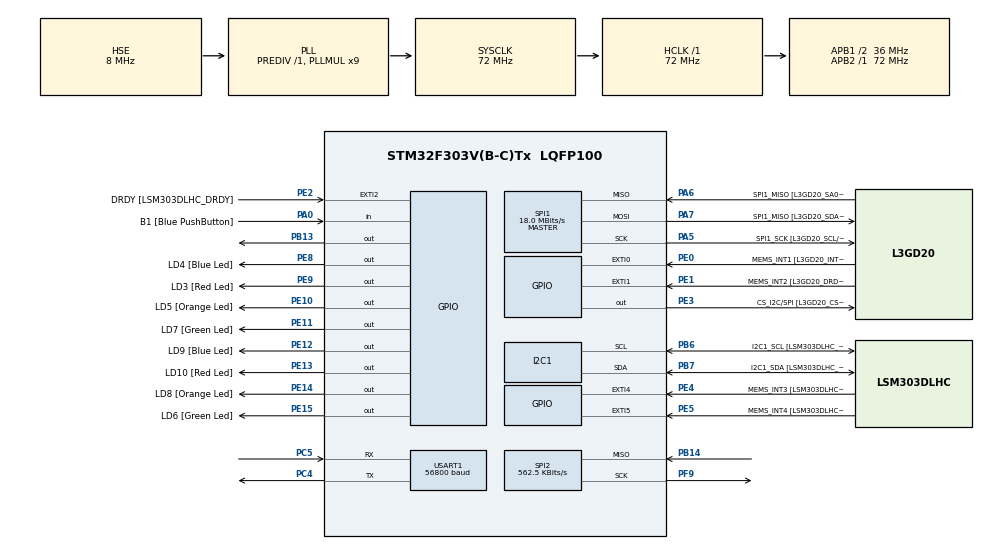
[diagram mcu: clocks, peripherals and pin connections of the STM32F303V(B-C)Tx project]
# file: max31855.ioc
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Mcu.Family=STM32F3
PA6.Mode=Full_Duplex_Master
RCC.CortexFreq_Value=72000000
SPI1.VirtualType=VM_MASTER
SPI2.VirtualType=VM_MASTER
PE11.GPIO_Label=LD7 [Green Led]
USART1.BaudRate=56800
PA14.GPIO_Label=SWCLK
RCC.SYSCLKSourceVirtual=RCC_SYSCLKSOURCE_PLLCLK
PA0.GPIO_Label=B1 [Blue PushButton]
PA6.GPIO_Label=SPI1_MISO [L3GD20_SA0/SDO]
PB6.GPIO_Label=I2C1_SCL [LSM303DLHC_SCL]
PC5.Mode=Asynchronous
PB13.Signal=GPIO_Output
PC15-OSC32_OUT.GPIO_Label=OSC32_OUT
ProjectManager.StackSize=0x400
VP_FREERTOS_VS_CMSIS_V2.Mode=CMSIS_V2
SPI1.Mode-Full_Duplex_Master=SPI_MODE_MASTER
PA12.Signal=USB_DP
SPI2.CLKPolarity=SPI_POLARITY_HIGH
SPI1.Direction=SPI_DIRECTION_2LINES
RCC.HCLKFreq_Value=72000000
RCC.APB2TimFreq_Value=72000000
PB6.Signal=I2C1_SCL
PB13.GPIO_ModeDefaultOutputPP=GPIO_MODE_OUTPUT_PP
PB6.Mode=I2C
SPI1.CalculateBaudRate=18.0 MBits/s
PE5.Signal=GPXTI5
PE1.Signal=GPXTI1
RCC.AHBFreq_Value=72000000
SPI2.BaudRatePrescaler=SPI_BAUDRATEPRESCALER_64
RCC.HSE_VALUE=8000000
PF0-OSC_IN.GPIO_Label=OSC_IN
RCC.PLLMUL=RCC_PLL_MUL9
NVIC.TIM1_TRG_COM_TIM17_IRQn=true\:0\:0\:false\:false\:true\:false\:false\:true
PF9.Mode=RX_Only_Simplex_Unidirect_Master
PE13.Signal=GPIO_Output
PE9.Signal=GPIO_Output
PA14.Mode=Serial_Wire
PB14.Mode=RX_Only_Simplex_Unidirect_Master
PE4.GPIO_Label=MEMS_INT3 [LSM303DLHC_INT1]
SPI2.CalculateBaudRate=562.5 KBits/s
PE2.Signal=GPXTI2
PB7.Signal=I2C1_SDA
PE10.Signal=GPIO_Output
PE4.Signal=GPXTI4
SPI1.CalculateBaudRate-Full_Duplex_Master=24.0 MBits/s
PA0.Signal=GPIO_Input
PB7.GPIO_Label=I2C1_SDA [LSM303DLHC_SDA]
Mcu.Package=LQFP100
PA6.Signal=SPI1_MISO
NVIC.TimeBase=TIM1_TRG_COM_TIM17_IRQn
SPI2.Mode=SPI_MODE_MASTER
NVIC.TimeBaseIP=TIM17
PE12.GPIO_Label=LD9 [Blue Led]
SPI2.CLKPhase=SPI_PHASE_2EDGE
PE0.GPIO_Label=MEMS_INT1 [L3GD20_INT1]
RCC.APB1TimFreq_Value=72000000
PC14-OSC32_IN.GPIO_Label=OSC32_IN
SPI2.Direction=SPI_DIRECTION_2LINES_RXONLY
PC5.Signal=USART1_RX
PE10.GPIO_Label=LD5 [Orange Led]
SPI1.BaudRatePrescaler=SPI_BAUDRATEPRESCALER_4
PE2.GPIO_Label=DRDY [LSM303DLHC_DRDY]
PF1-OSC_OUT.Signal=RCC_OSC_OUT
PC4.Mode=Asynchronous
PA5.Mode=Full_Duplex_Master
PB3.GPIO_Label=SWO
RCC.PLLSourceVirtual=RCC_PLLSOURCE_HSE
FREERTOS.Tasks01=defaultTask,24,128,StartDefaultTask,Default,NULL,Dynamic,NULL,NULL
PA7.Mode=Full_Duplex_Master
VP_SYS_VS_tim17.Mode=TIM17
PC4.Signal=USART1_TX
PE4.GPIO_ModeDefaultEXTI=GPIO_MODE_EVT_RISING
PA11.GPIO_Label=DM
PE14.GPIO_Label=LD8 [Orange Led]
PE1.GPIO_ModeDefaultEXTI=GPIO_MODE_EVT_RISING
RCC.APB1CLKDivider=RCC_HCLK_DIV2
PC14-OSC32_IN.Signal=RCC_OSC32_IN
PA12.GPIO_Label=DP
USART1.VirtualMode-Asynchronous=VM_ASYNC
PA13.Signal=SYS_JTMS-SWDIO
PE15.GPIO_Label=LD6 [Green Led]
ProjectManager.TargetToolchain=EWARM V8
PE5.GPIO_ModeDefaultEXTI=GPIO_MODE_EVT_RISING
PE8.GPIO_Label=LD4 [Blue Led]
PE0.GPIO_ModeDefaultEXTI=GPIO_MODE_EVT_RISING
PB13.GPIO_Speed=GPIO_SPEED_FREQ_HIGH
RCC.USBFreq_Value=48000000
PE11.Signal=GPIO_Output
RCC.LSE_VALUE=32768
PC15-OSC32_OUT.Signal=RCC_OSC32_OUT
PE9.GPIO_Label=LD3 [Red Led]
PF0-OSC_IN.Mode=HSE-External-Clock-Source
PB14.Signal=SPI2_MISO
PA5.Signal=SPI1_SCK
board=STM32F3DISCOVERY
PE1.GPIO_Label=MEMS_INT2 [L3GD20_DRDY/INT2]
PB13.GPIO_PuPd=GPIO_PULLUP
RCC.APB2Freq_Value=72000000
PE14.Signal=GPIO_Output
PE15.Signal=GPIO_Output
RCC.PRESCALERUSB=RCC_USBCLKSOURCE_PLL_DIV1_5
PE8.Signal=GPIO_Output
SPI1.Mode=SPI_MODE_MASTER
PF1-OSC_OUT.GPIO_Label=OSC_OUT
I2C1.Timing-I2C=0x2000090E
PA13.Mode=Serial_Wire
Mcu.Name=STM32F303V(B-C)Tx
PE0.Signal=GPXTI0
PE12.Signal=GPIO_Output
PA13.GPIO_Label=SWDIO
PB3.Signal=SYS_JTDO-TRACESWO
RCC.SYSCLKFreq_VALUE=72000000
PA7.GPIO_Label=SPI1_MISO [L3GD20_SDA/SDI/SDO]
PE13.GPIO_Label=LD10 [Red Led]
PA5.GPIO_Label=SPI1_SCK [L3GD20_SCL/SPC]
SPI2.FirstBit=SPI_FIRSTBIT_MSB
PE5.GPIO_Label=MEMS_INT4 [LSM303DLHC_INT2]
PB7.Mode=I2C
PA11.Signal=USB_DM
PA14.Signal=SYS_JTCK-SWCLK
ProjectManager.HeapSize=0x200
PF9.Signal=SPI2_SCK
RCC.HSI_VALUE=8000000
NVIC.PriorityGroup=NVIC_PRIORITYGROUP_4
PE3.Signal=GPIO_Output
PE3.GPIO_Label=CS_I2C/SPI [L3GD20_CS_I2C/SPI]
PE2.GPIO_ModeDefaultEXTI=GPIO_MODE_EVT_RISING
SPI2.DataSize=SPI_DATASIZE_16BIT
PF0-OSC_IN.Signal=RCC_OSC_IN
RCC.APB1Freq_Value=36000000
SPI1.BaudRatePrescaler-Full_Duplex_Master=SPI_BAUDRATEPRESCALER_2
PA7.Signal=SPI1_MOSI

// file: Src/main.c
/* USER CODE BEGIN Header */
/**
  ******************************************************************************
  * @file           : main.c
  * @brief          : Main program body
  ******************************************************************************
  * @attention
  *
  * <h2><center>&copy; Copyright (c) 2020 STMicroelectronics.
  * All rights reserved.</center></h2>
  *
  * This software component is licensed by ST under Ultimate Liberty license
  * SLA0044, the "License"; You may not use this file except in compliance with
  * the License. You may obtain a copy of the License at:
  *                             www.st.com/SLA0044
  *
  ******************************************************************************
  */
/* USER CODE END Header */

#include "main.h"
#include "cmsis_os.h"

/* USER CODE BEGIN Includes */
#include "MAX31855.h"
/* USER CODE END Includes */

I2C_HandleTypeDef hi2c1;

SPI_HandleTypeDef hspi1;
SPI_HandleTypeDef hspi2;

UART_HandleTypeDef huart1;

/* Definitions for defaultTask */
osThreadId_t defaultTaskHandle;
const osThreadAttr_t defaultTask_attributes = {
  .name = "defaultTask",
  .priority = (osPriority_t) osPriorityNormal,
  .stack_size = 128 * 4
};

void SystemClock_Config(void);
static void MX_GPIO_Init(void);
static void MX_I2C1_Init(void);
static void MX_SPI1_Init(void);
static void MX_SPI2_Init(void);
static void MX_USART1_UART_Init(void);
void StartDefaultTask(void *argument);

int main(void)
{

  /* MCU Configuration--------------------------------------------------------*/

  /* Reset of all peripherals, Initializes the Flash interface and the Systick. */
  HAL_Init();

  /* Configure the system clock */
  SystemClock_Config();

  /* Initialize all configured peripherals */
  MX_GPIO_Init();
  MX_I2C1_Init();
  MX_SPI1_Init();
  MX_SPI2_Init();
  MX_USART1_UART_Init();

  /* Init scheduler */
  osKernelInitialize();

  /* Create the thread(s) */
  /* creation of defaultTask */
  defaultTaskHandle = osThreadNew(StartDefaultTask, NULL, &defaultTask_attributes);

  /* Start scheduler */
  osKernelStart();

  /* We should never get here as control is now taken by the scheduler */
  /* Infinite loop */
  while (1)
  {

  }
}

void SystemClock_Config(void)
{
  RCC_OscInitTypeDef RCC_OscInitStruct = {0};
  RCC_ClkInitTypeDef RCC_ClkInitStruct = {0};
  RCC_PeriphCLKInitTypeDef PeriphClkInit = {0};

  /** Initializes the CPU, AHB and APB busses clocks
  */
  RCC_OscInitStruct.OscillatorType = RCC_OSCILLATORTYPE_HSI|RCC_OSCILLATORTYPE_HSE;
  RCC_OscInitStruct.HSEState = RCC_HSE_BYPASS;
  RCC_OscInitStruct.HSEPredivValue = RCC_HSE_PREDIV_DIV1;
  RCC_OscInitStruct.HSIState = RCC_HSI_ON;
  RCC_OscInitStruct.HSICalibrationValue = RCC_HSICALIBRATION_DEFAULT;
  RCC_OscInitStruct.PLL.PLLState = RCC_PLL_ON;
  RCC_OscInitStruct.PLL.PLLSource = RCC_PLLSOURCE_HSE;
  RCC_OscInitStruct.PLL.PLLMUL = RCC_PLL_MUL9;
  if (HAL_RCC_OscConfig(&RCC_OscInitStruct) != HAL_OK)
  {
    Error_Handler();
  }
  /** Initializes the CPU, AHB and APB busses clocks
  */
  RCC_ClkInitStruct.ClockType = RCC_CLOCKTYPE_HCLK|RCC_CLOCKTYPE_SYSCLK
                              |RCC_CLOCKTYPE_PCLK1|RCC_CLOCKTYPE_PCLK2;
  RCC_ClkInitStruct.SYSCLKSource = RCC_SYSCLKSOURCE_PLLCLK;
  RCC_ClkInitStruct.AHBCLKDivider = RCC_SYSCLK_DIV1;
  RCC_ClkInitStruct.APB1CLKDivider = RCC_HCLK_DIV2;
  RCC_ClkInitStruct.APB2CLKDivider = RCC_HCLK_DIV1;

  if (HAL_RCC_ClockConfig(&RCC_ClkInitStruct, FLASH_LATENCY_2) != HAL_OK)
  {
    Error_Handler();
  }
  PeriphClkInit.PeriphClockSelection = RCC_PERIPHCLK_USART1|RCC_PERIPHCLK_I2C1;
  PeriphClkInit.Usart1ClockSelection = RCC_USART1CLKSOURCE_PCLK2;
  PeriphClkInit.I2c1ClockSelection = RCC_I2C1CLKSOURCE_HSI;
  if (HAL_RCCEx_PeriphCLKConfig(&PeriphClkInit) != HAL_OK)
  {
    Error_Handler();
  }
}

static void MX_I2C1_Init(void)
{

  hi2c1.Instance = I2C1;
  hi2c1.Init.Timing = 0x2000090E;
  hi2c1.Init.OwnAddress1 = 0;
  hi2c1.Init.AddressingMode = I2C_ADDRESSINGMODE_7BIT;
  hi2c1.Init.DualAddressMode = I2C_DUALADDRESS_DISABLE;
  hi2c1.Init.OwnAddress2 = 0;
  hi2c1.Init.OwnAddress2Masks = I2C_OA2_NOMASK;
  hi2c1.Init.GeneralCallMode = I2C_GENERALCALL_DISABLE;
  hi2c1.Init.NoStretchMode = I2C_NOSTRETCH_DISABLE;
  if (HAL_I2C_Init(&hi2c1) != HAL_OK)
  {
    Error_Handler();
  }
  /** Configure Analogue filter
  */
  if (HAL_I2CEx_ConfigAnalogFilter(&hi2c1, I2C_ANALOGFILTER_ENABLE) != HAL_OK)
  {
    Error_Handler();
  }
  /** Configure Digital filter
  */
  if (HAL_I2CEx_ConfigDigitalFilter(&hi2c1, 0) != HAL_OK)
  {
    Error_Handler();
  }

}

static void MX_SPI1_Init(void)
{

  /* SPI1 parameter configuration*/
  hspi1.Instance = SPI1;
  hspi1.Init.Mode = SPI_MODE_MASTER;
  hspi1.Init.Direction = SPI_DIRECTION_2LINES;
  hspi1.Init.DataSize = SPI_DATASIZE_4BIT;
  hspi1.Init.CLKPolarity = SPI_POLARITY_LOW;
  hspi1.Init.CLKPhase = SPI_PHASE_1EDGE;
  hspi1.Init.NSS = SPI_NSS_SOFT;
  hspi1.Init.BaudRatePrescaler = SPI_BAUDRATEPRESCALER_4;
  hspi1.Init.FirstBit = SPI_FIRSTBIT_MSB;
  hspi1.Init.TIMode = SPI_TIMODE_DISABLE;
  hspi1.Init.CRCCalculation = SPI_CRCCALCULATION_DISABLE;
  hspi1.Init.CRCPolynomial = 7;
  hspi1.Init.CRCLength = SPI_CRC_LENGTH_DATASIZE;
  hspi1.Init.NSSPMode = SPI_NSS_PULSE_ENABLE;
  if (HAL_SPI_Init(&hspi1) != HAL_OK)
  {
    Error_Handler();
  }

}

static void MX_SPI2_Init(void)
{

  /* SPI2 parameter configuration*/
  hspi2.Instance = SPI2;
  hspi2.Init.Mode = SPI_MODE_MASTER;
  hspi2.Init.Direction = SPI_DIRECTION_2LINES_RXONLY;
  hspi2.Init.DataSize = SPI_DATASIZE_16BIT;
  hspi2.Init.CLKPolarity = SPI_POLARITY_HIGH;
  hspi2.Init.CLKPhase = SPI_PHASE_2EDGE;
  hspi2.Init.NSS = SPI_NSS_SOFT;
  hspi2.Init.BaudRatePrescaler = SPI_BAUDRATEPRESCALER_64;
  hspi2.Init.FirstBit = SPI_FIRSTBIT_MSB;
  hspi2.Init.TIMode = SPI_TIMODE_DISABLE;
  hspi2.Init.CRCCalculation = SPI_CRCCALCULATION_DISABLE;
  hspi2.Init.CRCPolynomial = 7;
  hspi2.Init.CRCLength = SPI_CRC_LENGTH_DATASIZE;
  hspi2.Init.NSSPMode = SPI_NSS_PULSE_DISABLE;
  if (HAL_SPI_Init(&hspi2) != HAL_OK)
  {
    Error_Handler();
  }

}

static void MX_USART1_UART_Init(void)
{

  huart1.Instance = USART1;
  huart1.Init.BaudRate = 56800;
  huart1.Init.WordLength = UART_WORDLENGTH_8B;
  huart1.Init.StopBits = UART_STOPBITS_1;
  huart1.Init.Parity = UART_PARITY_NONE;
  huart1.Init.Mode = UART_MODE_TX_RX;
  huart1.Init.HwFlowCtl = UART_HWCONTROL_NONE;
  huart1.Init.OverSampling = UART_OVERSAMPLING_16;
  huart1.Init.OneBitSampling = UART_ONE_BIT_SAMPLE_DISABLE;
  huart1.AdvancedInit.AdvFeatureInit = UART_ADVFEATURE_NO_INIT;
  if (HAL_UART_Init(&huart1) != HAL_OK)
  {
    Error_Handler();
  }

}

static void MX_GPIO_Init(void)
{
  GPIO_InitTypeDef GPIO_InitStruct = {0};

  /* GPIO Ports Clock Enable */
  __HAL_RCC_GPIOE_CLK_ENABLE();
  __HAL_RCC_GPIOC_CLK_ENABLE();
  __HAL_RCC_GPIOF_CLK_ENABLE();
  __HAL_RCC_GPIOA_CLK_ENABLE();
  __HAL_RCC_GPIOB_CLK_ENABLE();
  __HAL_RCC_GPIOD_CLK_ENABLE();

  /*Configure GPIO pin Output Level */
  HAL_GPIO_WritePin(GPIOE, CS_I2C_SPI_Pin|LD4_Pin|LD3_Pin|LD5_Pin
                          |LD7_Pin|LD9_Pin|LD10_Pin|LD8_Pin
                          |LD6_Pin, GPIO_PIN_RESET);

  /*Configure GPIO pin Output Level */
  HAL_GPIO_WritePin(GPIOB, GPIO_PIN_13, GPIO_PIN_RESET);

  /*Configure GPIO pins : DRDY_Pin MEMS_INT3_Pin MEMS_INT4_Pin MEMS_INT1_Pin
                           MEMS_INT2_Pin */
  GPIO_InitStruct.Pin = DRDY_Pin|MEMS_INT3_Pin|MEMS_INT4_Pin|MEMS_INT1_Pin
                          |MEMS_INT2_Pin;
  GPIO_InitStruct.Mode = GPIO_MODE_EVT_RISING;
  GPIO_InitStruct.Pull = GPIO_NOPULL;
  HAL_GPIO_Init(GPIOE, &GPIO_InitStruct);

  /*Configure GPIO pins : CS_I2C_SPI_Pin LD4_Pin LD3_Pin LD5_Pin
                           LD7_Pin LD9_Pin LD10_Pin LD8_Pin
                           LD6_Pin */
  GPIO_InitStruct.Pin = CS_I2C_SPI_Pin|LD4_Pin|LD3_Pin|LD5_Pin
                          |LD7_Pin|LD9_Pin|LD10_Pin|LD8_Pin
                          |LD6_Pin;
  GPIO_InitStruct.Mode = GPIO_MODE_OUTPUT_PP;
  GPIO_InitStruct.Pull = GPIO_NOPULL;
  GPIO_InitStruct.Speed = GPIO_SPEED_FREQ_LOW;
  HAL_GPIO_Init(GPIOE, &GPIO_InitStruct);

  /*Configure GPIO pins : PE6 PE7 */
  GPIO_InitStruct.Pin = GPIO_PIN_6|GPIO_PIN_7;
  GPIO_InitStruct.Mode = GPIO_MODE_ANALOG;
  GPIO_InitStruct.Pull = GPIO_NOPULL;
  HAL_GPIO_Init(GPIOE, &GPIO_InitStruct);

  /*Configure GPIO pins : PC13 PC0 PC1 PC2
                           PC3 PC6 PC7 PC8
                           PC9 PC10 PC11 PC12 */
  GPIO_InitStruct.Pin = GPIO_PIN_13|GPIO_PIN_0|GPIO_PIN_1|GPIO_PIN_2
                          |GPIO_PIN_3|GPIO_PIN_6|GPIO_PIN_7|GPIO_PIN_8
                          |GPIO_PIN_9|GPIO_PIN_10|GPIO_PIN_11|GPIO_PIN_12;
  GPIO_InitStruct.Mode = GPIO_MODE_ANALOG;
  GPIO_InitStruct.Pull = GPIO_NOPULL;
  HAL_GPIO_Init(GPIOC, &GPIO_InitStruct);

  /*Configure GPIO pins : PF10 PF2 PF4 PF6 */
  GPIO_InitStruct.Pin = GPIO_PIN_10|GPIO_PIN_2|GPIO_PIN_4|GPIO_PIN_6;
  GPIO_InitStruct.Mode = GPIO_MODE_ANALOG;
  GPIO_InitStruct.Pull = GPIO_NOPULL;
  HAL_GPIO_Init(GPIOF, &GPIO_InitStruct);

  /*Configure GPIO pin : B1_Pin */
  GPIO_InitStruct.Pin = B1_Pin;
  GPIO_InitStruct.Mode = GPIO_MODE_INPUT;
  GPIO_InitStruct.Pull = GPIO_NOPULL;
  HAL_GPIO_Init(B1_GPIO_Port, &GPIO_InitStruct);

  /*Configure GPIO pins : PA1 PA2 PA3 PA4
                           PA8 PA9 PA10 PA15 */
  GPIO_InitStruct.Pin = GPIO_PIN_1|GPIO_PIN_2|GPIO_PIN_3|GPIO_PIN_4
                          |GPIO_PIN_8|GPIO_PIN_9|GPIO_PIN_10|GPIO_PIN_15;
  GPIO_InitStruct.Mode = GPIO_MODE_ANALOG;
  GPIO_InitStruct.Pull = GPIO_NOPULL;
  HAL_GPIO_Init(GPIOA, &GPIO_InitStruct);

  /*Configure GPIO pins : PB0 PB1 PB2 PB10
                           PB11 PB12 PB15 PB4
                           PB5 PB8 PB9 */
  GPIO_InitStruct.Pin = GPIO_PIN_0|GPIO_PIN_1|GPIO_PIN_2|GPIO_PIN_10
                          |GPIO_PIN_11|GPIO_PIN_12|GPIO_PIN_15|GPIO_PIN_4
                          |GPIO_PIN_5|GPIO_PIN_8|GPIO_PIN_9;
  GPIO_InitStruct.Mode = GPIO_MODE_ANALOG;
  GPIO_InitStruct.Pull = GPIO_NOPULL;
  HAL_GPIO_Init(GPIOB, &GPIO_InitStruct);

  /*Configure GPIO pin : PB13 */
  GPIO_InitStruct.Pin = GPIO_PIN_13;
  GPIO_InitStruct.Mode = GPIO_MODE_OUTPUT_PP;
  GPIO_InitStruct.Pull = GPIO_PULLUP;
  GPIO_InitStruct.Speed = GPIO_SPEED_FREQ_HIGH;
  HAL_GPIO_Init(GPIOB, &GPIO_InitStruct);

  /*Configure GPIO pins : PD8 PD9 PD10 PD11
                           PD12 PD13 PD14 PD15
                           PD0 PD1 PD2 PD3
                           PD4 PD5 PD6 PD7 */
  GPIO_InitStruct.Pin = GPIO_PIN_8|GPIO_PIN_9|GPIO_PIN_10|GPIO_PIN_11
                          |GPIO_PIN_12|GPIO_PIN_13|GPIO_PIN_14|GPIO_PIN_15
                          |GPIO_PIN_0|GPIO_PIN_1|GPIO_PIN_2|GPIO_PIN_3
                          |GPIO_PIN_4|GPIO_PIN_5|GPIO_PIN_6|GPIO_PIN_7;
  GPIO_InitStruct.Mode = GPIO_MODE_ANALOG;
  GPIO_InitStruct.Pull = GPIO_NOPULL;
  HAL_GPIO_Init(GPIOD, &GPIO_InitStruct);

  /*Configure GPIO pins : DM_Pin DP_Pin */
  GPIO_InitStruct.Pin = DM_Pin|DP_Pin;
  GPIO_InitStruct.Mode = GPIO_MODE_AF_PP;
  GPIO_InitStruct.Pull = GPIO_NOPULL;
  GPIO_InitStruct.Speed = GPIO_SPEED_FREQ_HIGH;
  GPIO_InitStruct.Alternate = GPIO_AF14_USB;
  HAL_GPIO_Init(GPIOA, &GPIO_InitStruct);

}

void StartDefaultTask(void *argument)
{
  /* USER CODE BEGIN 5 */
  /* Infinite loop */
  uint8_t Buf[4];

  MAX31855_Sensor Fire_termocoupe_1;

  for(;;)
  {
    osDelay(1000);

    HAL_GPIO_WritePin(GPIOB,GPIO_PIN_13,GPIO_PIN_RESET);
    HAL_SPI_Receive(&hspi2,Buf,4,1000);
    HAL_GPIO_WritePin(GPIOB,GPIO_PIN_13,GPIO_PIN_SET);
    Fire_termocoupe_1.Buf=Buf;
    MAX31855_convert_buf(&Fire_termocoupe_1);

  }
  /* USER CODE END 5 */
}

 /**
  * @brief  Period elapsed callback in non blocking mode
  * @note   This function is called  when TIM17 interrupt took place, inside
  * HAL_TIM_IRQHandler(). It makes a direct call to HAL_IncTick() to increment
  * a global variable "uwTick" used as application time base.
  * @param  htim : TIM handle
  * @retval None
  */
void HAL_TIM_PeriodElapsedCallback(TIM_HandleTypeDef *htim)
{
  if (htim->Instance == TIM17) {
    HAL_IncTick();
  }
}

void Error_Handler(void)
{
}

/************************ (C) COPYRIGHT STMicroelectronics *****END OF FILE****/
